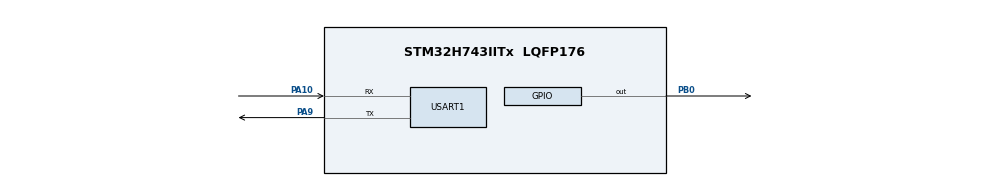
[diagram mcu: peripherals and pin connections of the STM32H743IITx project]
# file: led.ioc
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Dma.Request0=USART1_TX
Dma.Request1=USART1_RX
Dma.USART1_RX.1.Direction=DMA_PERIPH_TO_MEMORY
Dma.USART1_RX.1.EventEnable=DISABLE
Dma.USART1_RX.1.FIFOMode=DMA_FIFOMODE_DISABLE
Dma.USART1_RX.1.Instance=DMA1_Stream1
Dma.USART1_RX.1.MemDataAlignment=DMA_MDATAALIGN_BYTE
Dma.USART1_RX.1.MemInc=DMA_MINC_ENABLE
Dma.USART1_RX.1.Mode=DMA_NORMAL
Dma.USART1_RX.1.PeriphDataAlignment=DMA_PDATAALIGN_BYTE
Dma.USART1_RX.1.PeriphInc=DMA_PINC_DISABLE
Dma.USART1_RX.1.Polarity=HAL_DMAMUX_REQ_GEN_RISING
Dma.USART1_RX.1.Priority=DMA_PRIORITY_MEDIUM
Dma.USART1_RX.1.RequestNumber=1
Dma.USART1_RX.1.SignalID=NONE
Dma.USART1_RX.1.SyncEnable=DISABLE
Dma.USART1_RX.1.SyncPolarity=HAL_DMAMUX_SYNC_NO_EVENT
Dma.USART1_RX.1.SyncRequestNumber=1
Dma.USART1_RX.1.SyncSignalID=NONE
Dma.USART1_TX.0.Direction=DMA_MEMORY_TO_PERIPH
Dma.USART1_TX.0.EventEnable=DISABLE
Dma.USART1_TX.0.FIFOMode=DMA_FIFOMODE_DISABLE
Dma.USART1_TX.0.Instance=DMA1_Stream0
Dma.USART1_TX.0.MemDataAlignment=DMA_MDATAALIGN_BYTE
Dma.USART1_TX.0.MemInc=DMA_MINC_ENABLE
Dma.USART1_TX.0.Mode=DMA_NORMAL
Dma.USART1_TX.0.PeriphDataAlignment=DMA_PDATAALIGN_BYTE
Dma.USART1_TX.0.PeriphInc=DMA_PINC_DISABLE
Dma.USART1_TX.0.Polarity=HAL_DMAMUX_REQ_GEN_RISING
Dma.USART1_TX.0.Priority=DMA_PRIORITY_MEDIUM
Dma.USART1_TX.0.RequestNumber=1
Dma.USART1_TX.0.SignalID=NONE
Dma.USART1_TX.0.SyncEnable=DISABLE
Dma.USART1_TX.0.SyncPolarity=HAL_DMAMUX_SYNC_NO_EVENT
Dma.USART1_TX.0.SyncRequestNumber=1
Dma.USART1_TX.0.SyncSignalID=NONE
Mcu.Family=STM32H7
Mcu.Name=STM32H743IITx
Mcu.Package=LQFP176
NVIC.DMA1_Stream0_IRQn=true\:0\:0\:false\:false\:true\:false\:true\:true
NVIC.DMA1_Stream1_IRQn=true\:0\:0\:false\:false\:true\:false\:true\:true
NVIC.PriorityGroup=NVIC_PRIORITYGROUP_4
NVIC.USART1_IRQn=true\:0\:0\:false\:false\:true\:true\:true\:true
PA10.Mode=Asynchronous
PA10.Signal=USART1_RX
PA9.Mode=Asynchronous
PA9.Signal=USART1_TX
PB0.Signal=GPIO_Output
PH0-OSC_IN\ (PH0).Mode=HSE-External-Oscillator
PH0-OSC_IN\ (PH0).Signal=RCC_OSC_IN
PH1-OSC_OUT\ (PH1).Mode=HSE-External-Oscillator
PH1-OSC_OUT\ (PH1).Signal=RCC_OSC_OUT
ProjectManager.HeapSize=0x200
ProjectManager.StackSize=0x400
ProjectManager.TargetToolchain=EWARM V8
RCC.ADCFreq_Value=50390625
RCC.APB1Freq_Value=62500000
RCC.APB2Freq_Value=62500000
RCC.APB3Freq_Value=62500000
RCC.APB4Freq_Value=62500000
RCC.CortexFreq_Value=250000000
RCC.D1PPRE=RCC_APB3_DIV2
RCC.D2PPRE1=RCC_APB1_DIV2
RCC.D2PPRE2=RCC_APB2_DIV2
RCC.D3PPRE=RCC_APB4_DIV2
RCC.DIVM1=2
RCC.DIVN1=40
RCC.HCLKFreq_Value=125000000
RCC.HPRE=RCC_HCLK_DIV2
RCC.HSE_VALUE=25000000
RCC.PLL2FRACN=0
RCC.PLL3FRACN=0
RCC.PLLFRACN=0
RCC.PLLSourceVirtual=RCC_PLLSOURCE_HSE
RCC.SYSCLKFreq_VALUE=250000000
RCC.SYSCLKSource=RCC_SYSCLKSOURCE_PLLCLK
RCC.USBFreq_Value=250000000
USART1.VirtualMode-Asynchronous=VM_ASYNC
board=custom

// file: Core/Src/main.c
/* USER CODE BEGIN Header */
/**
  ******************************************************************************
  * @file           : main.c
  * @brief          : Main program body
  ******************************************************************************
  * @attention
  *
  * Copyright (c) 2023 STMicroelectronics.
  * All rights reserved.
  *
  * This software is licensed under terms that can be found in the LICENSE file
  * in the root directory of this software component.
  * If no LICENSE file comes with this software, it is provided AS-IS.
  *
  ******************************************************************************
  */
/* USER CODE END Header */
#include "main.h"
#include "dma.h"
#include "usart.h"
#include "gpio.h"

void SystemClock_Config(void);

/* USER CODE BEGIN 0 */

extern UART_HandleTypeDef huart1;

#include <string.h>

uint8_t UART_RECV_BUF[UART_BUF_SIZE];

struct A_D  A_data;

void test_dma(void)
{

	memcpy(A_data.TEXT_TO_SEND, UART_RECV_BUF, A_data.len);
	HAL_UART_Transmit_DMA(&huart1,A_data.TEXT_TO_SEND,A_data.len);

}

/* USER CODE END 0 */

int main(void)
{

  /* MCU Configuration--------------------------------------------------------*/

  /* Reset of all peripherals, Initializes the Flash interface and the Systick. */
  HAL_Init();

  /* Configure the system clock */
  SystemClock_Config();

  /* Initialize all configured peripherals */
  MX_GPIO_Init();
  MX_DMA_Init();
  MX_USART1_UART_Init();
  /* USER CODE BEGIN 2 */

  HAL_UART_Receive_DMA(&huart1, UART_RECV_BUF, UART_BUF_SIZE); /* 启动DMA接收 */
  __HAL_UART_ENABLE_IT(&huart1, UART_IT_IDLE); /* 使能串口空闲中断 */

  /* USER CODE END 2 */

  /* Infinite loop */
  /* USER CODE BEGIN WHILE */
  while (1)
  {
		HAL_Delay(100);
		HAL_GPIO_TogglePin(GPIOB, GPIO_PIN_0);
		if(A_data.flag == 1)
		{
			test_dma();
			A_data.flag = 0;
		}
    /* USER CODE END WHILE */

  }
}

void SystemClock_Config(void)
{
  RCC_OscInitTypeDef RCC_OscInitStruct = {0};
  RCC_ClkInitTypeDef RCC_ClkInitStruct = {0};

  /** Supply configuration update enable
  */
  HAL_PWREx_ConfigSupply(PWR_LDO_SUPPLY);

  /** Configure the main internal regulator output voltage
  */
  __HAL_PWR_VOLTAGESCALING_CONFIG(PWR_REGULATOR_VOLTAGE_SCALE2);

  while(!__HAL_PWR_GET_FLAG(PWR_FLAG_VOSRDY)) {}

  /** Initializes the RCC Oscillators according to the specified parameters
  * in the RCC_OscInitTypeDef structure.
  */
  RCC_OscInitStruct.OscillatorType = RCC_OSCILLATORTYPE_HSE;
  RCC_OscInitStruct.HSEState = RCC_HSE_ON;
  RCC_OscInitStruct.PLL.PLLState = RCC_PLL_ON;
  RCC_OscInitStruct.PLL.PLLSource = RCC_PLLSOURCE_HSE;
  RCC_OscInitStruct.PLL.PLLM = 2;
  RCC_OscInitStruct.PLL.PLLN = 40;
  RCC_OscInitStruct.PLL.PLLP = 2;
  RCC_OscInitStruct.PLL.PLLQ = 2;
  RCC_OscInitStruct.PLL.PLLR = 2;
  RCC_OscInitStruct.PLL.PLLRGE = RCC_PLL1VCIRANGE_3;
  RCC_OscInitStruct.PLL.PLLVCOSEL = RCC_PLL1VCOWIDE;
  RCC_OscInitStruct.PLL.PLLFRACN = 0;
  if (HAL_RCC_OscConfig(&RCC_OscInitStruct) != HAL_OK)
  {
    Error_Handler();
  }

  /** Initializes the CPU, AHB and APB buses clocks
  */
  RCC_ClkInitStruct.ClockType = RCC_CLOCKTYPE_HCLK|RCC_CLOCKTYPE_SYSCLK
                              |RCC_CLOCKTYPE_PCLK1|RCC_CLOCKTYPE_PCLK2
                              |RCC_CLOCKTYPE_D3PCLK1|RCC_CLOCKTYPE_D1PCLK1;
  RCC_ClkInitStruct.SYSCLKSource = RCC_SYSCLKSOURCE_PLLCLK;
  RCC_ClkInitStruct.SYSCLKDivider = RCC_SYSCLK_DIV1;
  RCC_ClkInitStruct.AHBCLKDivider = RCC_HCLK_DIV2;
  RCC_ClkInitStruct.APB3CLKDivider = RCC_APB3_DIV2;
  RCC_ClkInitStruct.APB1CLKDivider = RCC_APB1_DIV2;
  RCC_ClkInitStruct.APB2CLKDivider = RCC_APB2_DIV2;
  RCC_ClkInitStruct.APB4CLKDivider = RCC_APB4_DIV2;

  if (HAL_RCC_ClockConfig(&RCC_ClkInitStruct, FLASH_LATENCY_2) != HAL_OK)
  {
    Error_Handler();
  }
}

void Error_Handler(void)
{
  __disable_irq();
  while (1)
  {
  }
}
